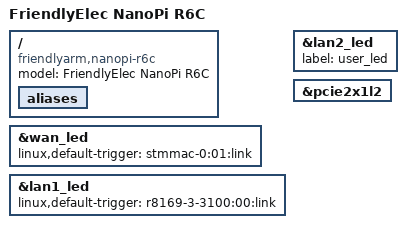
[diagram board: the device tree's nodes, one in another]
// SPDX-License-Identifier: (GPL-2.0+ OR MIT)

/dts-v1/;

#include "rk3588s-nanopi-r6s.dts"

/ {
	model = "FriendlyElec NanoPi R6C";
	compatible = "friendlyarm,nanopi-r6c", "rockchip,rk3588s";

	aliases {
		/delete-property/ ethernet2;
	};
};

&wan_led {
	linux,default-trigger = "stmmac-0:01:link";
};

&lan1_led {
	linux,default-trigger = "r8169-3-3100:00:link";
};

&lan2_led {
	/delete-property/ linux,default-trigger;
	label = "user_led";
};

&pcie2x1l2 {
	/delete-node/ pcie@0,0;
};
